AUTOSAR XML (schema 4-0-3)
standard types defined: Boolean, UInt16, UInt32
package /AUTOSAR_Platform/DataConstrs
  range DC_Boolean: raw 0..1
  range DC_UInt16: raw 0..65535
package /PATAC/MSM/ComponentTypes
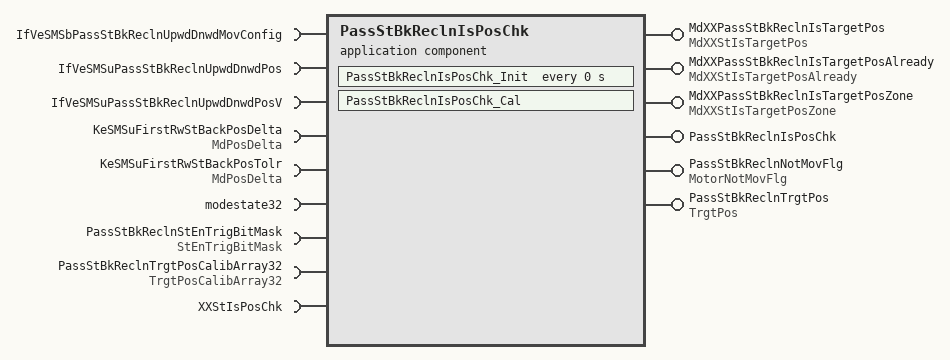
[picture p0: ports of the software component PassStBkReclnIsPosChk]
  application sw component type PassStBkReclnIsPosChk
    6 x provide port:
      MdXXPassStBkReclnIsTargetPos: nonqueued-sender-com-spec{data-element=MdXXStIsTargetPos/Val, init-value=0}, provided-interface=MdXXStIsTargetPos
      MdXXPassStBkReclnIsTargetPosAlready: nonqueued-sender-com-spec{data-element=MdXXStIsTargetPosAlready/Val, init-value=0}, provided-interface=MdXXStIsTargetPosAlready
      MdXXPassStBkReclnIsTargetPosZone: nonqueued-sender-com-spec{data-element=MdXXStIsTargetPosZone/Val, init-value=0}, provided-interface=MdXXStIsTargetPosZone
      PassStBkReclnIsPosChk: server-com-spec{operation=PassStBkReclnIsPosChk/Cal, queue-length=1}, provided-interface=PassStBkReclnIsPosChk
      PassStBkReclnNotMovFlg: nonqueued-sender-com-spec{data-element=MotorNotMovFlg/Val, init-value=0}, provided-interface=MotorNotMovFlg
      PassStBkReclnTrgtPos: nonqueued-sender-com-spec{data-element=TrgtPos/Val, init-value=4095}, provided-interface=TrgtPos
    9 x require port:
      IfVeSMSbPassStBkReclnUpwdDnwdMovConfig: nonqueued-receiver-com-spec{data-element=IfVeSMSbPassStBkReclnUpwdDnwdMovConfig/Val, filter=data-filter-type=ALWAYS, init-value=0}, required-interface=IfVeSMSbPassStBkReclnUpwdDnwdMovConfig
      IfVeSMSuPassStBkReclnUpwdDnwdPos: nonqueued-receiver-com-spec{data-element=IfVeSMSuPassStBkReclnUpwdDnwdPos/Val, filter=data-filter-type=ALWAYS, init-value=0}, required-interface=IfVeSMSuPassStBkReclnUpwdDnwdPos
      IfVeSMSuPassStBkReclnUpwdDnwdPosV: nonqueued-receiver-com-spec{data-element=IfVeSMSuPassStBkReclnUpwdDnwdPosV/Val, filter=data-filter-type=ALWAYS, init-value=0}, required-interface=IfVeSMSuPassStBkReclnUpwdDnwdPosV
      KeSMSuFirstRwStBackPosDelta: parameter-require-com-spec{init-value=150, parameter=Val}, required-interface=MdPosDelta
      KeSMSuFirstRwStBackPosTolr: parameter-require-com-spec{init-value=150, parameter=Val}, required-interface=MdPosDelta
      modestate32: nonqueued-receiver-com-spec{data-element=modestate32/Val, filter=data-filter-type=ALWAYS, init-value=0}, required-interface=modestate32
      PassStBkReclnStEnTrigBitMask: nonqueued-receiver-com-spec{data-element=StEnTrigBitMask/Val, filter=data-filter-type=ALWAYS, init-value=0}, required-interface=StEnTrigBitMask
      PassStBkReclnTrgtPosCalibArray32: nonqueued-receiver-com-spec{data-element=TrgtPosArray32, filter=data-filter-type=ALWAYS, init-value=96 x 4095}, required-interface=TrgtPosCalibArray32
      XXStIsPosChk: client-com-spec=XXStIsPosChk/Cal, required-interface=XXStIsPosChk
    behavior PassStBkReclnIsPosChk_InternalBehavior
      operation invoked event OIT_PassStBkReclnIsPosChk_Cal_PassStBkReclnIsPosChk_Cal: start-on-event=PassStBkReclnIsPosChk_Cal, operation=PassStBkReclnIsPosChk.Cal
      timing event PassStBkReclnIsPosChk_InitEvent: start-on-event=PassStBkReclnIsPosChk_Init, period=0
      runnable PassStBkReclnIsPosChk_Cal
        data-receive-point-by-arguments:
          6 x access:
            REC_IfVeSMSbPassStBkReclnUpwdDnwdMovConfig_Val: accessed-variable=IfVeSMSbPassStBkReclnUpwdDnwdMovConfig.Val
            REC_IfVeSMSuPassStBkReclnUpwdDnwdPos_Val: accessed-variable=IfVeSMSuPassStBkReclnUpwdDnwdPos.Val
            REC_IfVeSMSuPassStBkReclnUpwdDnwdPosV_Val: accessed-variable=IfVeSMSuPassStBkReclnUpwdDnwdPosV.Val
            REC_modestate32_Val: accessed-variable=modestate32.Val
            REC_PassStBkReclnStEnTrigBitMask_Val: accessed-variable=PassStBkReclnStEnTrigBitMask.Val
            REC_PassStBkReclnTrgtPosCalibArray32_TrgtPosArray32: accessed-variable=PassStBkReclnTrgtPosCalibArray32.TrgtPosArray32
        data-send-points:
          5 x access:
            SEND_MdXXPassStBkReclnIsTargetPos_Val: accessed-variable=MdXXPassStBkReclnIsTargetPos.Val
            SEND_MdXXPassStBkReclnIsTargetPosAlready_Val: accessed-variable=MdXXPassStBkReclnIsTargetPosAlready.Val
            SEND_MdXXPassStBkReclnIsTargetPosZone_Val: accessed-variable=MdXXPassStBkReclnIsTargetPosZone.Val
            SEND_PassStBkReclnNotMovFlg_Val: accessed-variable=PassStBkReclnNotMovFlg.Val
            SEND_PassStBkReclnTrgtPos_Val: accessed-variable=PassStBkReclnTrgtPos.Val
        parameter access PA_KeSMSuFirstRwStBackPosDelta_Val: accessed-parameter=KeSMSuFirstRwStBackPosDelta.Val
        parameter access PA_KeSMSuFirstRwStBackPosTolr_Val: accessed-parameter=KeSMSuFirstRwStBackPosTolr.Val
        sync call SC_XXStIsPosChk_Cal: operation=XXStIsPosChk.Cal, timeout=0
      runnable PassStBkReclnIsPosChk_Init
        parameter access PA_KeSMSuFirstRwStBackPosDelta_Val: accessed-parameter=KeSMSuFirstRwStBackPosDelta.Val
        parameter access PA_KeSMSuFirstRwStBackPosTolr_Val: accessed-parameter=KeSMSuFirstRwStBackPosTolr.Val
  swc implementation PassStBkReclnIsPosChk_Implementation: behavior=PassStBkReclnIsPosChk_InternalBehavior
    code-descriptors:
      code Default: artifact-descriptors=autosar-engineering-object={short-label=Default, category=SWSRC}
package /PATAC/MSM/ModeAdjust/CalPortInterface
  parameter interface MdPosDelta
    parameter data prototype Val: sw-calibration-access=READ-WRITE, type=UInt16
package /PATAC/MSM/ModeAdjust/DataType
  impl type TrgtPosCalibArray32: category=ARRAY, sw-calibration-access=READ-ONLY, type-emitter=RTE  # 0:pos 1:max 2:min
    element Element: array-size=96, array-size-semantics=FIXED-SIZE, implementation-data-type=UInt16, invalid-value=0
package /PATAC/MSM/ModeAdjust/Interfaces
  sender receiver interface IfVeSMSuPassStBkReclnUpwdDnwdPosV: invalidation-policy{data-element=IfVeSMSuPassStBkReclnUpwdDnwdPosV/Val, handle-invalid=DONT-INVALIDATE}
    data Val: type=Implementation/Boolean
package /PATAC/MSM/ModeAdjust/PortInterface
  client server interface PassStBkReclnIsPosChk
    operation Cal
  client server interface XXStIsPosChk
    operation Cal
      13 x arg, all with server-argument-impl-policy=USE-ARGUMENT-TYPE:
        MdCalibArray32: type=TrgtPosCalibArray32, direction=IN
        Pos: type=UInt16, direction=IN
        PosV: type=DataTypes/Boolean, direction=IN
        MovConfig: type=DataTypes/Boolean, direction=IN
        modestate32: type=UInt32, direction=IN
        IsPos: type=UInt32, direction=OUT
        IsPosAlready: type=UInt32, direction=OUT
        IsPosZone: type=UInt32, direction=OUT
        NotMovFlg: type=DataTypes/Boolean, direction=OUT
        StTrgtPos: type=UInt16, direction=OUT
        PosDelta: type=UInt16, direction=IN
        PosTolr: type=UInt16, direction=IN
        StBitMask: type=UInt32, direction=IN
  7 x sender receiver interface:
    MdXXStIsTargetPos: invalidation-policy{data-element=MdXXStIsTargetPos/Val, handle-invalid=DONT-INVALIDATE}
      data Val: type=UInt32
    MdXXStIsTargetPosAlready: invalidation-policy{data-element=MdXXStIsTargetPosAlready/Val, handle-invalid=DONT-INVALIDATE}
      data Val: type=UInt32
    MdXXStIsTargetPosZone: invalidation-policy{data-element=MdXXStIsTargetPosZone/Val, handle-invalid=DONT-INVALIDATE}
      data Val: type=UInt32
    modestate32: invalidation-policy{data-element=modestate32/Val, handle-invalid=DONT-INVALIDATE}
      data Val: type=UInt32
    MotorNotMovFlg: invalidation-policy{data-element=MotorNotMovFlg/Val, handle-invalid=DONT-INVALIDATE}
      data Val: type=Implementation/Boolean
    StEnTrigBitMask: invalidation-policy{data-element=StEnTrigBitMask/Val, handle-invalid=DONT-INVALIDATE}
      data Val: type=UInt32
    TrgtPosCalibArray32: invalidation-policy{data-element=TrgtPosArray32, handle-invalid=DONT-INVALIDATE}
      data TrgtPosArray32: type=TrgtPosCalibArray32  # 0:Pos 1:Max 2:Min
package /PATAC/MSM/PortInterfaces
  sender receiver interface IfVeSMSbPassStBkReclnUpwdDnwdMovConfig: invalidation-policy{data-element=IfVeSMSbPassStBkReclnUpwdDnwdMovConfig/Val, handle-invalid=DONT-INVALIDATE}
    data Val: type=Implementation/Boolean
  sender receiver interface IfVeSMSuPassStBkReclnUpwdDnwdPos: invalidation-policy{data-element=IfVeSMSuPassStBkReclnUpwdDnwdPos/Val, handle-invalid=DONT-INVALIDATE}
    data Val: type=UInt16
  sender receiver interface TrgtPos: invalidation-policy{data-element=TrgtPos/Val, handle-invalid=DONT-INVALIDATE}
    data Val: type=UInt16
